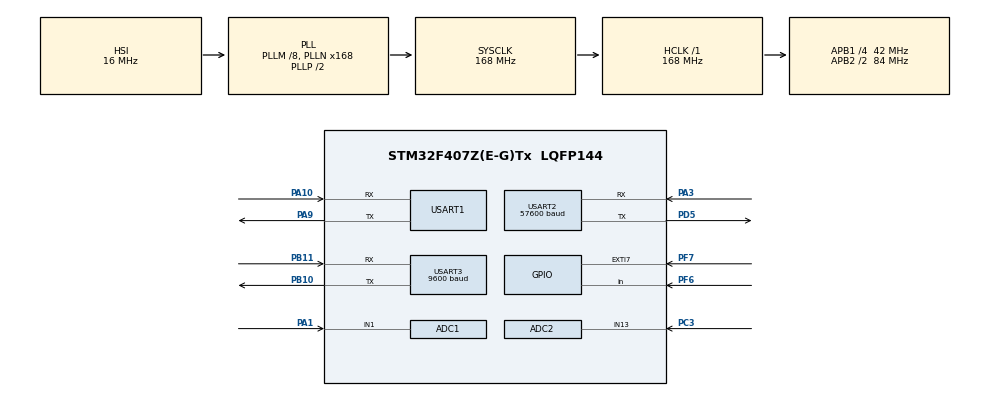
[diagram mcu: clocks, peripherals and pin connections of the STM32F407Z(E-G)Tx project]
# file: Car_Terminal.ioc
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ADC1.Channel-0\#ChannelRegularConversion=ADC_CHANNEL_1
ADC1.ClockPrescaler=ADC_CLOCK_SYNC_PCLK_DIV6
ADC1.NbrOfConversionFlag=1
ADC1.Rank-0\#ChannelRegularConversion=1
ADC1.SamplingTime-0\#ChannelRegularConversion=ADC_SAMPLETIME_3CYCLES
ADC1.master=1
ADC2.Channel-1\#ChannelRegularConversion=ADC_CHANNEL_13
ADC2.ClockPrescaler=ADC_CLOCK_SYNC_PCLK_DIV6
ADC2.NbrOfConversionFlag=1
ADC2.Rank-1\#ChannelRegularConversion=1
ADC2.SamplingTime-1\#ChannelRegularConversion=ADC_SAMPLETIME_3CYCLES
Mcu.Family=STM32F4
Mcu.Name=STM32F407Z(E-G)Tx
Mcu.Package=LQFP144
NVIC.EXTI9_5_IRQn=true\:1\:0\:true\:false\:true\:true\:true\:true
NVIC.PriorityGroup=NVIC_PRIORITYGROUP_4
NVIC.RCC_IRQn=true\:0\:0\:false\:false\:true\:true\:false\:true
NVIC.TIM2_IRQn=true\:14\:0\:true\:false\:true\:true\:true\:true
PA1.Signal=ADCx_IN1
PA10.Mode=Asynchronous
PA10.Signal=USART1_RX
PA3.Mode=Asynchronous
PA3.Signal=USART2_RX
PA9.Mode=Asynchronous
PA9.Signal=USART1_TX
PB10.Mode=Asynchronous
PB10.Signal=USART3_TX
PB11.Mode=Asynchronous
PB11.Signal=USART3_RX
PC3.Signal=ADCx_IN13
PD5.Mode=Asynchronous
PD5.Signal=USART2_TX
PF6.GPIO_PuPd=GPIO_PULLUP
PF6.Signal=GPIO_Input
PF7.GPIO_ModeDefaultEXTI=GPIO_MODE_IT_RISING
PF7.GPIO_PuPd=GPIO_PULLDOWN
PF7.Signal=GPXTI7
ProjectManager.HeapSize=0x200
ProjectManager.StackSize=0x400
ProjectManager.TargetToolchain=MDK-ARM V5
RCC.48MHZClocksFreq_Value=84000000
RCC.AHBFreq_Value=168000000
RCC.APB1CLKDivider=RCC_HCLK_DIV4
RCC.APB1Freq_Value=42000000
RCC.APB1TimFreq_Value=84000000
RCC.APB2CLKDivider=RCC_HCLK_DIV2
RCC.APB2Freq_Value=84000000
RCC.APB2TimFreq_Value=168000000
RCC.CortexFreq_Value=168000000
RCC.HCLKFreq_Value=168000000
RCC.HSE_VALUE=25000000
RCC.HSI_VALUE=16000000
RCC.LSE_VALUE=32768
RCC.PLLM=8
RCC.PLLN=168
RCC.SYSCLKFreq_VALUE=168000000
RCC.SYSCLKSource=RCC_SYSCLKSOURCE_PLLCLK
RCC.VCOOutputFreq_Value=336000000
SH.ADCx_IN1.0=ADC1_IN1,IN1
SH.ADCx_IN13.0=ADC2_IN13,IN13
TIM2.AutoReloadPreload=TIM_AUTORELOAD_PRELOAD_ENABLE
TIM2.ClockDivision=TIM_CLOCKDIVISION_DIV4
TIM2.CounterMode=TIM_COUNTERMODE_DOWN
TIM2.Period=2000
TIM2.Prescaler=42000
USART1.VirtualMode=VM_ASYNC
USART2.BaudRate=57600
USART2.VirtualMode=VM_ASYNC
USART3.BaudRate=9600
USART3.VirtualMode=VM_ASYNC
VP_TIM2_VS_ClockSourceINT.Mode=Internal
board=custom

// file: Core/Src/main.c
/* USER CODE BEGIN Header */
/**
  ******************************************************************************
  * @file           : main.c
  * @brief          : Main program body
  ******************************************************************************
  * @attention
  *
  * Copyright (c) 2024 STMicroelectronics.
  * All rights reserved.
  *
  * This software is licensed under terms that can be found in the LICENSE file
  * in the root directory of this software component.
  * If no LICENSE file comes with this software, it is provided AS-IS.
  *
  ******************************************************************************
  */
/* USER CODE END Header */
#include "main.h"
#include "adc.h"
#include "tim.h"
#include "usart.h"
#include "gpio.h"

/* USER CODE BEGIN Includes */
#include "MyCallbackFunc.h"
#include "ZW0623.h"
#include "string.h"
/* USER CODE END Includes */

void SystemClock_Config(void);

int main(void)
{

  /* MCU Configuration--------------------------------------------------------*/

  /* Reset of all peripherals, Initializes the Flash interface and the Systick. */
  HAL_Init();

  /* Configure the system clock */
  SystemClock_Config();

  /* Initialize all configured peripherals */
  MX_GPIO_Init();
  MX_ADC1_Init();
  MX_ADC2_Init();
  MX_TIM2_Init();
  MX_USART1_UART_Init();
  MX_USART2_UART_Init();
  MX_USART3_UART_Init();
  /* USER CODE BEGIN 2 */
//HAL_TIM_Base_Start_IT(&htim2);
  /* USER CODE END 2 */
	uint8_t cmd_handshake[] = {0xEF, 0x01, 0xFF, 0xFF, 0xFF, 0xFF, 0x01, 0x00, 0x03, 0x13, 0x00, 0x17};
	uint32_t p=0;
//PS_HandShake(&p);
	//HAL_UART_Transmit(&huart1,(uint8_t *)&p,16,100);
//Add_FR();
uint32_t Addr;
  /* Infinite loop */
  while (1)
  {

    /* USER CODE BEGIN 3 */
		if(PS_HandShake(&Addr))
		{

			//HAL_UART_Transmit(&huart1,(uint8_t *)"是应答包",32,100);
		}

		HAL_Delay(100);

  }
  /* USER CODE END 3 */
}

void SystemClock_Config(void)
{
  RCC_OscInitTypeDef RCC_OscInitStruct = {0};
  RCC_ClkInitTypeDef RCC_ClkInitStruct = {0};

  /** Configure the main internal regulator output voltage
  */
  __HAL_RCC_PWR_CLK_ENABLE();
  __HAL_PWR_VOLTAGESCALING_CONFIG(PWR_REGULATOR_VOLTAGE_SCALE1);

  /** Initializes the RCC Oscillators according to the specified parameters
  * in the RCC_OscInitTypeDef structure.
  */
  RCC_OscInitStruct.OscillatorType = RCC_OSCILLATORTYPE_HSI;
  RCC_OscInitStruct.HSIState = RCC_HSI_ON;
  RCC_OscInitStruct.HSICalibrationValue = RCC_HSICALIBRATION_DEFAULT;
  RCC_OscInitStruct.PLL.PLLState = RCC_PLL_ON;
  RCC_OscInitStruct.PLL.PLLSource = RCC_PLLSOURCE_HSI;
  RCC_OscInitStruct.PLL.PLLM = 8;
  RCC_OscInitStruct.PLL.PLLN = 168;
  RCC_OscInitStruct.PLL.PLLP = RCC_PLLP_DIV2;
  RCC_OscInitStruct.PLL.PLLQ = 4;
  if (HAL_RCC_OscConfig(&RCC_OscInitStruct) != HAL_OK)
  {
    Error_Handler();
  }

  /** Initializes the CPU, AHB and APB buses clocks
  */
  RCC_ClkInitStruct.ClockType = RCC_CLOCKTYPE_HCLK|RCC_CLOCKTYPE_SYSCLK
                              |RCC_CLOCKTYPE_PCLK1|RCC_CLOCKTYPE_PCLK2;
  RCC_ClkInitStruct.SYSCLKSource = RCC_SYSCLKSOURCE_PLLCLK;
  RCC_ClkInitStruct.AHBCLKDivider = RCC_SYSCLK_DIV1;
  RCC_ClkInitStruct.APB1CLKDivider = RCC_HCLK_DIV4;
  RCC_ClkInitStruct.APB2CLKDivider = RCC_HCLK_DIV2;

  if (HAL_RCC_ClockConfig(&RCC_ClkInitStruct, FLASH_LATENCY_5) != HAL_OK)
  {
    Error_Handler();
  }
}

void Error_Handler(void)
{
  __disable_irq();
  while (1)
  {
  }
}
